# ATA5702M322 device description
Architecture: AVR8; Family: megaAVR
Registers are 8-bit, access not given, no defined reset value unless marked. A register's access mark holds for its fields unless they carry their own. Offsets are from the block's base; [hi:lo] are bit positions; {n}, {i} and the like mark numbered series.

## LF_RECEIVER
Instances: LF_RECEIVER 0x00
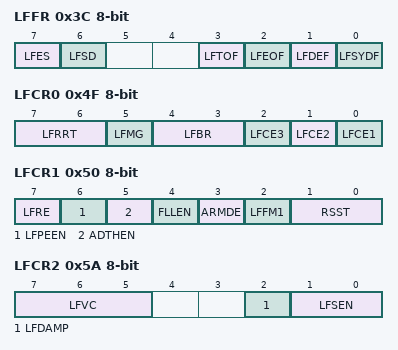
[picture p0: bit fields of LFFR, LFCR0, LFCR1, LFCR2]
0x3C LFFR — LF Receiver Flag Register
  [7] LFES — LF Envelope Signal
  [6] LFSD — LF Signal Detect
  [3] LFTOF — LF telegram Time Out Flag
  [2] LFEOF — LF End of Telegram Flag
  [1] LFDEF — LF Decoder Error Flag
  [0] LFSYDF — LF Synchronization Detect Flag
0x4F LFCR0 — LF Receiver Control Register 0
  [7:6] LFRRT — LF Receiver Reset Time
    0=128 us; 1=160 us; 2=192 us; 3=224 us
  [5] LFMG — LF Receiver Maximum Gain Select
  [4:3] LFBR — LF Receiver Bit Rate
    0=1.95 kBit/s; 1=3.90 kBit/s; 2=7.81 kBit/s
  [2] LFCE3 — LF Receiver Channel 3 Enable
  [1] LFCE2 — LF Receiver Channel 2 Enable
  [0] LFCE1 — LF Receiver Channel 1 Enable
0x50 LFCR1 — LF Receiver Control Register 1
  [7] LFRE — LF Receiver Enable
  [6] LFPEEN — LF Port Event Enable
  [5] ADTHEN — Adapt Threshold Enable
  [4] FLLEN — FLL Enable
  [3] ARMDE — Analog Reset Manchester Detector Enable
  [2] LFFM1 — LF Function Mode bit 1
  [1:0] RSST — RSSI Startup Time
    0=256 us; 1=384 us; 2=512 us; 3=640 us
0x5A LFCR2 — LF Receiver Control Register 2
  [7:5] LFVC — LF Velocity Control
  [2] LFDAMP — LF coil Damping level select
  [1:0] LFSEN — LF Sensitivity Mode
    0=High Sensitivity; 1=Medium Sensitivity; 2=Low Sensitivity
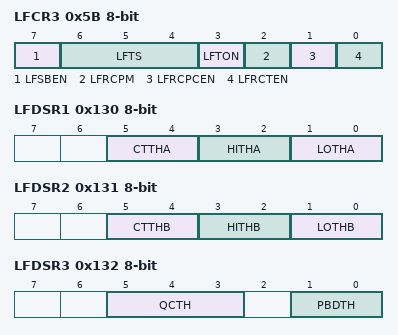
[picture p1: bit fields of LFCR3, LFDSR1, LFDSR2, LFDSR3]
0x5B LFCR3 — LF Receiver Control Register 3
  [7] LFSBEN — LF Standby mode Enable
  [6:4] LFTS — LF Standby Time
    0=384 us; 1=768 us; 2=1152 us; 3=1536 us; 4=2304 us; 5=3072 us; 6=4608 us; 7=6144 us
  [3] LFTON — LF On Time with Activated Standby Mode
  [2] LFRCPM — LF RC Pump mode Enable
  [1] LFRCPCEN — LF RC Pump Continuous Enable
  [0] LFRCTEN — LF RC Trim Enable
0x130 LFDSR1 — LF Receiver Decoder Setting Register 1
  [5:4] CTTHA — Count Threshold A
  [3:2] HITHA — High Threshold A
  [1:0] LOTHA — Low Threshold A
0x131 LFDSR2 — LF Receiver Decoder Setting Register 2
  [5:4] CTTHB — Count Threshold B
  [3:2] HITHB — High Threshold B
  [1:0] LOTHB — Low Threshold B
0x132 LFDSR3 — LF Receiver Decoder Setting Register 3
  [5:3] QCTH — Quality Check Threshold
  [1:0] PBDTH — Preburst Detection Threshold
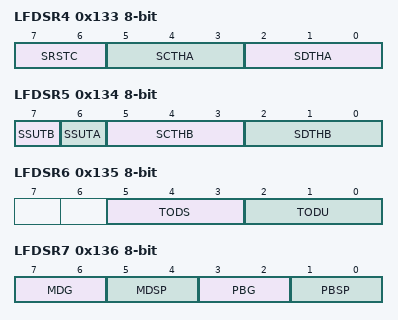
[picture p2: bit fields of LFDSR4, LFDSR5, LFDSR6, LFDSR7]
0x133 LFDSR4 — LF Receiver Decoder Setting Register 4
  [7:6] SRSTC — Sync Restart Control
  [5:3] SCTHA — Sync Count Threshold A
  [2:0] SDTHA — Sync Detection Threshold A
0x134 LFDSR5 — LF Decoder Setting 5 Register
  [7] SSUTB — Snyc Start-Up Time B
  [6] SSUTA — Snyc Start-Up Time A
  [5:3] SCTHB — Sync Count Threshold B
  [2:0] SDTHB — Sync Detection Threshold B
0x135 LFDSR6 — LF Decoder Setting 6 Register
  [5:3] TODS — Time Out Timer Delta Sync detect
  [2:0] TODU — Time Out Decode Unit
0x136 LFDSR7 — LF Decoder Setting 7 Register
  [7:6] MDG — FLL Manchester Detector Gain
  [5:4] MDSP — FLL Manchester Detector Speed
  [3:2] PBG — FLL Preburst Gain
  [1:0] PBSP — FLL Preburst Speed
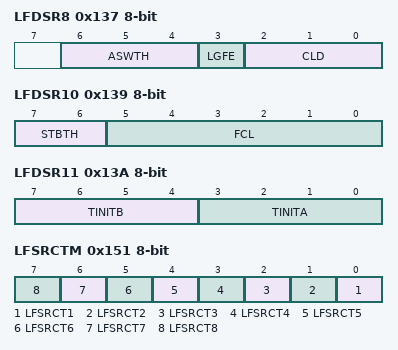
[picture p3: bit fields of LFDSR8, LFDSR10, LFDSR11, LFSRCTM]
0x137 LFDSR8 — LF Decoder Setting 8 Register
  [6:4] ASWTH — Adaptive Switch Threshold
  [3] LGFE — Loop Gain Fading Enable
  [2:0] CLD — Counter Limit Delta
0x138 LFDSR9 — LF Decoder Setting 9 Register
  [4:0] STW — Step Width
0x139 LFDSR10 — LF Decoder Setting 10 Register
  [7:6] STBTH — Stop Bit Correlator Threshold
  [5:0] FCL — Frequency Control Limit
0x13A LFDSR11 — Low Frequency Decoder Setting Register 11
  [7:4] TINITB — Time Init B
  [3:0] TINITA — Time Init A
0x151 LFSRCTM — LF Receiver SRC Tuning MSB
  [n-1] LFSRCT{n} (n=1..8) — LF Receiver SRC Tuning Tuning value
0x15C LFSRCTL — LF Receiver SRC Tuning LSB
  [0] LFSRCT0 — LF Receiver SRC Tuning Tuning value
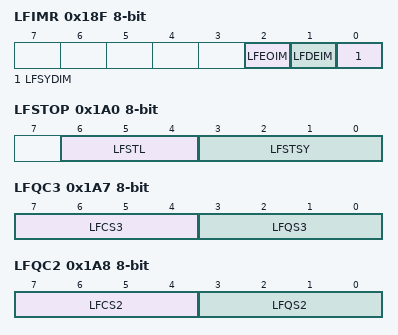
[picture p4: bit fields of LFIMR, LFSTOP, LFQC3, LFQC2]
0x18F LFIMR — LF Receiver Interrupt Mask Register
  [2] LFEOIM — LF End Of telegram Interrupt Mask
  [1] LFDEIM — LF Decoder Error Interrupt Mask
  [0] LFSYDIM — LF Synchronization Detected Interrupt Mask
0x19B LFSYSY 32-bit — LF Receiver Synchronization Symbols Register
0x19F LFSYLE — LF Receiver Synchronization Length Register
  [5:0] LFSYLE
0x1A0 LFSTOP — LF Receiver Stop Bit Register
  [6:4] LFSTL — LF Stop Bits Length
  [3:0] LFSTSY — LF Stop Bits Symbols
0x1A7 LFQC3 — LF Receiver Channel 3 Quality Faktor Register
  [7:4] LFCS3 — LF capacitor select channel 3
  [3:0] LFQS3 — LF resistor select channel 3
0x1A8 LFQC2 — LF Receiver Channel 2 Quality Faktor Register
  [7:4] LFCS2 — LF capacitor select channel 2
  [3:0] LFQS2 — LF resistor select channel 2
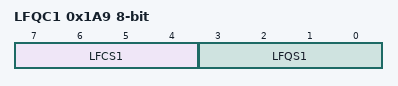
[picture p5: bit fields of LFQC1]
0x1A9 LFQC1 — LF Receiver Channel 1 Quality Faktor Register
  [7:4] LFCS1 — LF capacitor select channel 1
  [3:0] LFQS1 — LF resistor select channel 1
